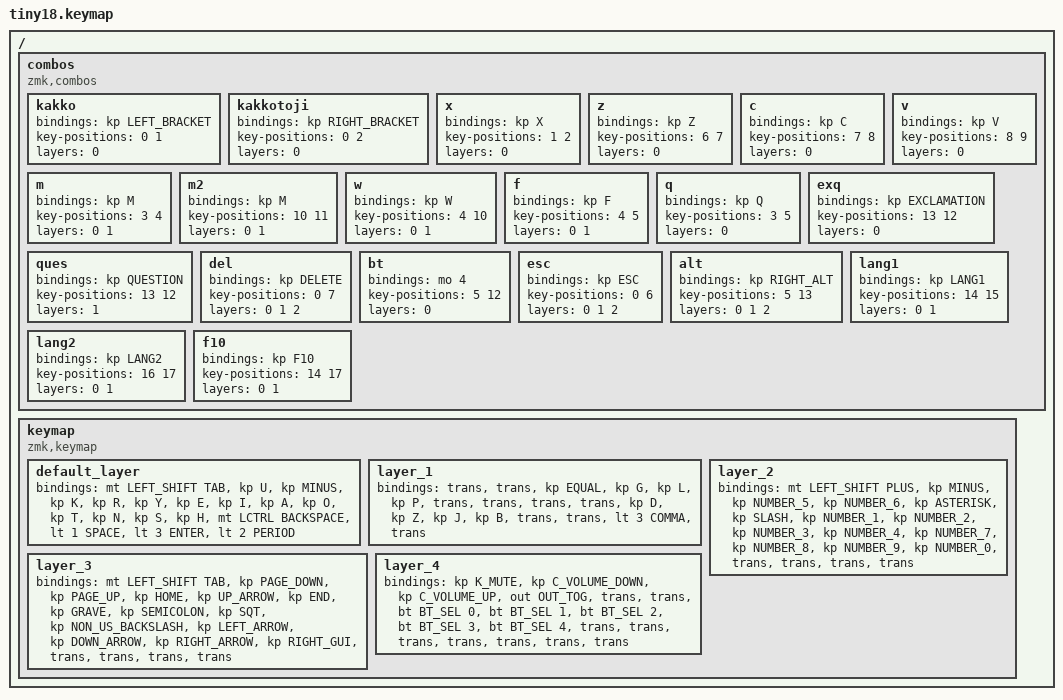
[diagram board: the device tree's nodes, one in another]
#include <input/processors.dtsi>
#include <dt-bindings/zmk/input_transform.h>
#include <zephyr/dt-bindings/input/input-event-codes.h>
#include <behaviors.dtsi>
#include <dt-bindings/zmk/bt.h>
#include <dt-bindings/zmk/keys.h>
#include <dt-bindings/zmk/outputs.h>

/ {
    combos {
        compatible = "zmk,combos";

        kakko {
            bindings = <&kp LEFT_BRACKET>;
            key-positions = <0 1>;
            layers = <0>;
        };

        kakkotoji {
            bindings = <&kp RIGHT_BRACKET>;
            key-positions = <0 2>;
            layers = <0>;
        };

        x {
            bindings = <&kp X>;
            key-positions = <1 2>;
            layers = <0>;
        };

        z {
            bindings = <&kp Z>;
            key-positions = <6 7>;
            layers = <0>;
        };

        c {
            bindings = <&kp C>;
            key-positions = <7 8>;
            layers = <0>;
        };

        v {
            bindings = <&kp V>;
            key-positions = <8 9>;
            layers = <0>;
        };

        m {
            bindings = <&kp M>;
            key-positions = <3 4>;
            layers = <0 1>;
        };

        m2 {
            bindings = <&kp M>;
            key-positions = <10 11>;
            layers = <0 1>;
        };

        w {
            bindings = <&kp W>;
            key-positions = <4 10>;
            layers = <0 1>;
        };

        f {
            bindings = <&kp F>;
            key-positions = <4 5>;
            layers = <0 1>;
        };

        q {
            bindings = <&kp Q>;
            key-positions = <3 5>;
            layers = <0>;
        };

        exq {
            bindings = <&kp EXCLAMATION>;
            key-positions = <13 12>;
            layers = <0>;
        };

        ques {
            bindings = <&kp QUESTION>;
            key-positions = <13 12>;
            layers = <1>;
        };

        del {
            bindings = <&kp DELETE>;
            key-positions = <0 7>;
            layers = <0 1 2>;
        };

        bt {
            bindings = <&mo 4>;
            key-positions = <5 12>;
            layers = <0>;
        };

        esc {
            bindings = <&kp ESC>;
            key-positions = <0 6>;
            layers = <0 1 2>;
        };

        alt {
            bindings = <&kp RIGHT_ALT>;
            key-positions = <5 13>;
            layers = <0 1 2>;
        };

        lang1 {
            bindings = <&kp LANG1>;
            key-positions = <14 15>;
            layers = <0 1>;
        };

        lang2 {
            bindings = <&kp LANG2>;
            key-positions = <16 17>;
            layers = <0 1>;
        };

        f10 {
            bindings = <&kp F10>;
            key-positions = <14 17>;
            layers = <0 1>;
        };
    };

    keymap {
        compatible = "zmk,keymap";

        default_layer {
            bindings = <
&mt LEFT_SHIFT TAB  &kp U  &kp MINUS  &kp K  &kp R  &kp Y  &kp E  &kp I  &kp A  &kp O  &kp T  &kp N  &kp S  &kp H  &mt LCTRL BACKSPACE  &lt 1 SPACE  &lt 3 ENTER  &lt 2 PERIOD
            >;
        };

        layer_1 {
            bindings = <
&trans  &trans  &kp EQUAL  &kp G  &kp L  &kp P  &trans  &trans  &trans  &trans  &kp D  &kp Z  &kp J  &kp B  &trans  &trans  &lt 3 COMMA  &trans
            >;
        };

        layer_2 {
            bindings = <
&mt LEFT_SHIFT PLUS  &kp MINUS  &kp NUMBER_5  &kp NUMBER_6  &kp ASTERISK  &kp SLASH  &kp NUMBER_1  &kp NUMBER_2  &kp NUMBER_3  &kp NUMBER_4  &kp NUMBER_7  &kp NUMBER_8  &kp NUMBER_9  &kp NUMBER_0  &trans  &trans  &trans  &trans
            >;
        };

        layer_3 {
            bindings = <
&mt LEFT_SHIFT TAB  &kp PAGE_DOWN  &kp PAGE_UP  &kp HOME  &kp UP_ARROW  &kp END  &kp GRAVE  &kp SEMICOLON  &kp SQT  &kp NON_US_BACKSLASH  &kp LEFT_ARROW  &kp DOWN_ARROW  &kp RIGHT_ARROW  &kp RIGHT_GUI  &trans  &trans  &trans  &trans
            >;
        };

        layer_4 {
            bindings = <
&kp K_MUTE  &kp C_VOLUME_DOWN  &kp C_VOLUME_UP  &out OUT_TOG  &trans  &trans  &bt BT_SEL 0  &bt BT_SEL 1  &bt BT_SEL 2  &bt BT_SEL 3  &bt BT_SEL 4  &trans  &trans  &trans  &trans  &trans  &trans  &trans
            >;
        };
    };
};
